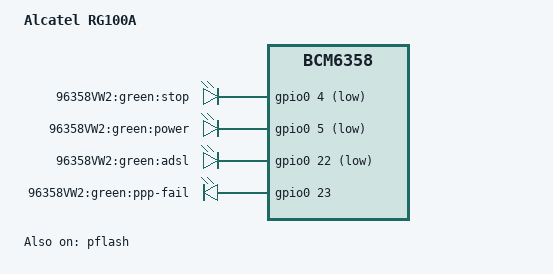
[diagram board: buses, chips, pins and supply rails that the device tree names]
/dts-v1/;

#include "bcm6358.dtsi"

#include <dt-bindings/input/input.h>

/ {
	model = "Alcatel RG100A";
	compatible = "alcatel,rg100a", "brcm,bcm6358";

	gpio-leds {
		compatible = "gpio-leds";

		stop_green {
			label = "96358VW2:green:stop";
			gpios = <&gpio0 4 1>;
		};
		power_green {
			label = "96358VW2:green:power";
			gpios = <&gpio0 5 1>;
			default-state = "on";
		};
		adsl_green {
			label = "96358VW2:green:adsl";
			gpios = <&gpio0 22 1>;
		};
		ppp_fail_green {
			label = "96358VW2:green:ppp-fail";
			gpios = <&gpio0 23 0>;
		};
	};
};

&pflash {
	status = "ok";

	linux,part-probe = "bcm63xxpart";

	cfe@0 {
		label = "CFE";
		reg = <0x000000 0x020000>;
		read-only;
	};

	linux@20000 {
		label = "linux";
		reg = <0x020000 0xfc0000>;
	};

	nvram@fe0000 {
		label = "nvram";
		reg = <0xfe0000 0x020000>;
	};
};
